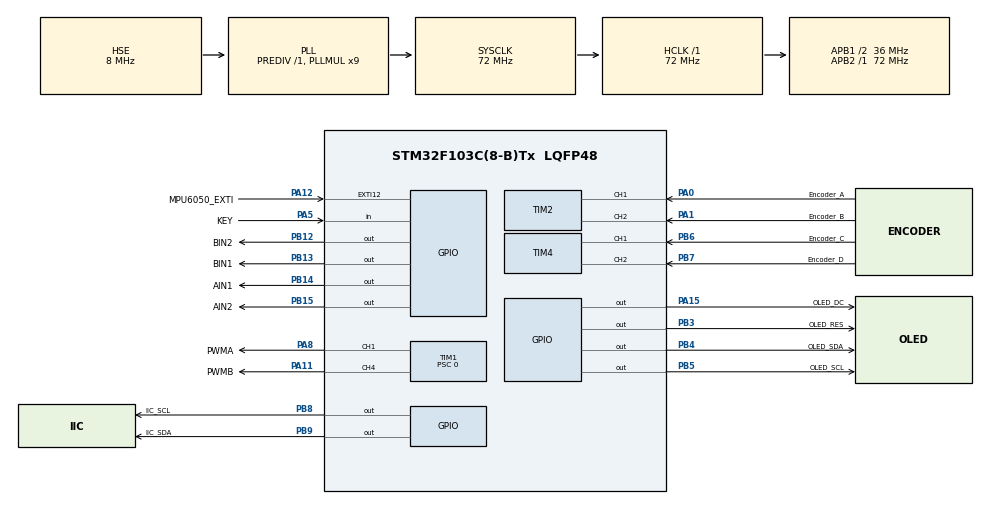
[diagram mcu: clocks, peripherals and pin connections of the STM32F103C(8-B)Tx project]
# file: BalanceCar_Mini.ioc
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Mcu.Family=STM32F1
Mcu.Name=STM32F103C(8-B)Tx
Mcu.Package=LQFP48
NVIC.EXTI15_10_IRQn=true\:2\:1\:true\:false\:true\:true\:true\:true
NVIC.PriorityGroup=NVIC_PRIORITYGROUP_2
PA0-WKUP.GPIO_Label=Encoder_A
PA0-WKUP.Signal=S_TIM2_CH1_ETR
PA1.GPIO_Label=Encoder_B
PA1.Signal=S_TIM2_CH2
PA11.GPIO_Label=PWMB
PA11.GPIO_Speed=GPIO_SPEED_FREQ_HIGH
PA11.Signal=S_TIM1_CH4
PA12.GPIO_Label=MPU6050_EXTI
PA12.GPIO_ModeDefaultEXTI=GPIO_MODE_IT_FALLING
PA12.GPIO_PuPd=GPIO_PULLUP
PA12.Signal=GPXTI12
PA13.Mode=Serial_Wire
PA13.Signal=SYS_JTMS-SWDIO
PA14.Mode=Serial_Wire
PA14.Signal=SYS_JTCK-SWCLK
PA15.GPIO_Label=OLED_DC
PA15.GPIO_Speed=GPIO_SPEED_FREQ_MEDIUM
PA15.Signal=GPIO_Output
PA5.GPIO_Label=KEY
PA5.GPIO_PuPd=GPIO_PULLUP
PA5.Signal=GPIO_Input
PA8.GPIO_Label=PWMA
PA8.GPIO_Speed=GPIO_SPEED_FREQ_HIGH
PA8.Signal=S_TIM1_CH1
PB12.GPIO_Label=BIN2
PB12.GPIO_Speed=GPIO_SPEED_FREQ_HIGH
PB12.Signal=GPIO_Output
PB13.GPIO_Label=BIN1
PB13.GPIO_Speed=GPIO_SPEED_FREQ_HIGH
PB13.Signal=GPIO_Output
PB14.GPIO_Label=AIN1
PB14.GPIO_Speed=GPIO_SPEED_FREQ_HIGH
PB14.Signal=GPIO_Output
PB15.GPIO_Label=AIN2
PB15.GPIO_Speed=GPIO_SPEED_FREQ_HIGH
PB15.Signal=GPIO_Output
PB3.GPIO_Label=OLED_RES
PB3.GPIO_Speed=GPIO_SPEED_FREQ_MEDIUM
PB3.Signal=GPIO_Output
PB4.GPIO_Label=OLED_SDA
PB4.GPIO_Speed=GPIO_SPEED_FREQ_MEDIUM
PB4.Signal=GPIO_Output
PB5.GPIO_Label=OLED_SCL
PB5.GPIO_Speed=GPIO_SPEED_FREQ_MEDIUM
PB5.Signal=GPIO_Output
PB6.GPIO_Label=Encoder_C
PB6.Signal=S_TIM4_CH1
PB7.GPIO_Label=Encoder_D
PB7.Signal=S_TIM4_CH2
PB8.GPIO_Label=IIC_SCL
PB8.GPIO_Speed=GPIO_SPEED_FREQ_HIGH
PB8.PinState=GPIO_PIN_SET
PB8.Signal=GPIO_Output
PB9.GPIO_Label=IIC_SDA
PB9.GPIO_Speed=GPIO_SPEED_FREQ_HIGH
PB9.PinState=GPIO_PIN_SET
PB9.Signal=GPIO_Output
PD0-OSC_IN.Mode=HSE-External-Oscillator
PD0-OSC_IN.Signal=RCC_OSC_IN
PD1-OSC_OUT.Mode=HSE-External-Oscillator
PD1-OSC_OUT.Signal=RCC_OSC_OUT
ProjectManager.HeapSize=0x200
ProjectManager.StackSize=0x400
ProjectManager.TargetToolchain=SW4STM32
RCC.AHBFreq_Value=72000000
RCC.APB1CLKDivider=RCC_HCLK_DIV2
RCC.APB1Freq_Value=36000000
RCC.APB1TimFreq_Value=72000000
RCC.APB2Freq_Value=72000000
RCC.APB2TimFreq_Value=72000000
RCC.HCLKFreq_Value=72000000
RCC.PLLMUL=RCC_PLL_MUL9
RCC.PLLSourceVirtual=RCC_PLLSOURCE_HSE
RCC.SYSCLKFreq_VALUE=72000000
RCC.SYSCLKSource=RCC_SYSCLKSOURCE_PLLCLK
RCC.TimSys_Div=SYSTICK_CLKSOURCE_HCLK_DIV8
RCC.USBFreq_Value=72000000
SH.S_TIM1_CH1.0=TIM1_CH1,PWM Generation1 CH1
SH.S_TIM1_CH4.0=TIM1_CH4,PWM Generation4 CH4
SH.S_TIM2_CH1_ETR.0=TIM2_CH1,Encoder_Interface
SH.S_TIM2_CH2.0=TIM2_CH2,Encoder_Interface
SH.S_TIM4_CH1.0=TIM4_CH1,Encoder_Interface
SH.S_TIM4_CH2.0=TIM4_CH2,Encoder_Interface
TIM1.AutoReloadPreload=TIM_AUTORELOAD_PRELOAD_ENABLE
TIM1.Channel-PWM\ Generation1\ CH1=TIM_CHANNEL_1
TIM1.Channel-PWM\ Generation4\ CH4=TIM_CHANNEL_4
TIM1.Period=7200-1
TIM1.Prescaler=0
TIM2.EncoderMode=TIM_ENCODERMODE_TI12
TIM2.IC1Filter=10
TIM2.IC2Filter=10
TIM4.EncoderMode=TIM_ENCODERMODE_TI12
TIM4.IC1Filter=10
TIM4.IC2Filter=10
board=custom

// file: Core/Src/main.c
/* USER CODE BEGIN Header */
/**
  ******************************************************************************
  * @file           : main.c
  * @brief          : Main program body
  ******************************************************************************
  * @attention
  *
  * <h2><center>&copy; Copyright (c) 2021 STMicroelectronics.
  * All rights reserved.</center></h2>
  *
  * This software component is licensed by ST under BSD 3-Clause license,
  * the "License"; You may not use this file except in compliance with the
  * License. You may obtain a copy of the License at:
  *                        opensource.org/licenses/BSD-3-Clause
  *
  ******************************************************************************
  */
/* USER CODE END Header */
#include "main.h"
#include "tim.h"
#include "gpio.h"

/* USER CODE BEGIN Includes */
#include "sys.h"
/* USER CODE END Includes */

/* USER CODE BEGIN PTD */
u8 Flag_Stop = 1;                            //电机停止标志位，默认关闭
int Encoder_Left, Encoder_Right;       //左右编码器的脉冲计数
float Angle_Balance, Gyro_Balance;        //平衡倾角 平衡陀螺仪
/* USER CODE END PTD */

void SystemClock_Config(void);

int main(void) {

    /* MCU Configuration--------------------------------------------------------*/

    /* Reset of all peripherals, Initializes the Flash interface and the Systick. */
    HAL_Init();

    /* Configure the system clock */
    SystemClock_Config();

    /* Initialize all configured peripherals */
    MX_GPIO_Init();
    MX_TIM1_Init();
    MX_TIM2_Init();
    MX_TIM4_Init();
    /* USER CODE BEGIN 2 */
    delay_init();                            //延时函数初始化
    JTAG_Set(JTAG_SWD_DISABLE);         //关闭JTAG接口
    JTAG_Set(SWD_ENABLE);               //打开SWD接口 可以利用主板的SWD接口调试
    OLED_Init();                        //OLED初始化
    MPU6050_initialize();               //MPU6050初始化
    DMP_Init();                         //初始化DMP
    HAL_NVIC_EnableIRQ(EXTI15_10_IRQn); //开启引脚外部中断
    /* USER CODE END 2 */

    /* Infinite loop */
    /* USER CODE BEGIN WHILE */
    while (1) {
//        oled_show();            //显示屏打开
        /* USER CODE END WHILE */

    }
}

void SystemClock_Config(void) {
    RCC_OscInitTypeDef RCC_OscInitStruct = {0};
    RCC_ClkInitTypeDef RCC_ClkInitStruct = {0};

    /** Initializes the RCC Oscillators according to the specified parameters
    * in the RCC_OscInitTypeDef structure.
    */
    RCC_OscInitStruct.OscillatorType = RCC_OSCILLATORTYPE_HSE;
    RCC_OscInitStruct.HSEState = RCC_HSE_ON;
    RCC_OscInitStruct.HSEPredivValue = RCC_HSE_PREDIV_DIV1;
    RCC_OscInitStruct.HSIState = RCC_HSI_ON;
    RCC_OscInitStruct.PLL.PLLState = RCC_PLL_ON;
    RCC_OscInitStruct.PLL.PLLSource = RCC_PLLSOURCE_HSE;
    RCC_OscInitStruct.PLL.PLLMUL = RCC_PLL_MUL9;
    if (HAL_RCC_OscConfig(&RCC_OscInitStruct) != HAL_OK) {
        Error_Handler();
    }
    /** Initializes the CPU, AHB and APB buses clocks
    */
    RCC_ClkInitStruct.ClockType = RCC_CLOCKTYPE_HCLK | RCC_CLOCKTYPE_SYSCLK
                                  | RCC_CLOCKTYPE_PCLK1 | RCC_CLOCKTYPE_PCLK2;
    RCC_ClkInitStruct.SYSCLKSource = RCC_SYSCLKSOURCE_PLLCLK;
    RCC_ClkInitStruct.AHBCLKDivider = RCC_SYSCLK_DIV1;
    RCC_ClkInitStruct.APB1CLKDivider = RCC_HCLK_DIV2;
    RCC_ClkInitStruct.APB2CLKDivider = RCC_HCLK_DIV1;

    if (HAL_RCC_ClockConfig(&RCC_ClkInitStruct, FLASH_LATENCY_2) != HAL_OK) {
        Error_Handler();
    }
}

void Error_Handler(void) {
    __disable_irq();
    while (1) {
    }
}
